AUTOSAR XML (schema 4-2-2)
package /COM_SWC
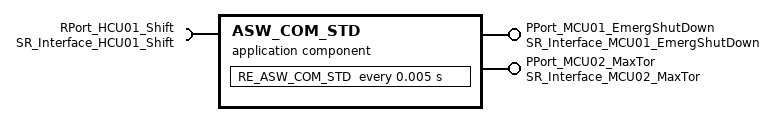
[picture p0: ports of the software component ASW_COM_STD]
  application sw component type ASW_COM_STD
    provide port PPort_MCU01_EmergShutDown: provided-interface=SR_Interface_MCU01_EmergShutDown
    provide port PPort_MCU02_MaxTor: provided-interface=SR_Interface_MCU02_MaxTor
    require port RPort_HCU01_Shift: nonqueued-receiver-com-spec{alive-timeout=0.3, data-element=HCU01_Shift}, required-interface=SR_Interface_HCU01_Shift
    behavior IB_ASW_COM_STD
      timing event TE_5ms_RE_ASW_COM_STD: start-on-event=RE_ASW_COM_STD, period=0.005
      runnable RE_ASW_COM_STD
        data-receive-point-by-arguments:
          access REC_HCU01_Shift: accessed-variable=RPort_HCU01_Shift.HCU01_Shift
        data-send-points:
          access SEND_MCU01_EmergShutDown: accessed-variable=PPort_MCU01_EmergShutDown.MCU01_EmergShutDown
          access SEND_MCU02_MaxTor: accessed-variable=PPort_MCU02_MaxTor.MCU02_MaxTor
